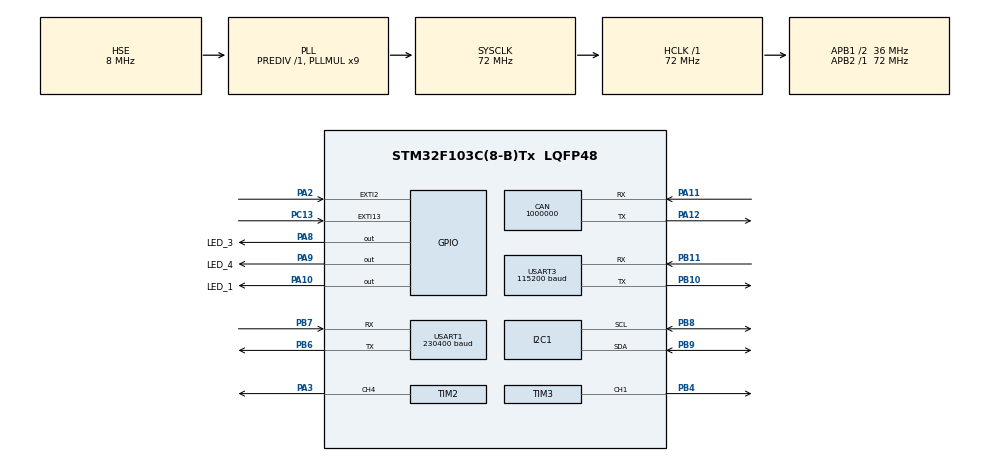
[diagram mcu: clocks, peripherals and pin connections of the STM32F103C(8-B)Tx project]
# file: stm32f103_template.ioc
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CAN.CalculateBaudRate=1000000
CAN.CalculateTimeBit=1000
CAN.CalculateTimeQuantum=83.33333333333333
Dma.I2C1_RX.2.Direction=DMA_PERIPH_TO_MEMORY
Dma.I2C1_RX.2.Instance=DMA1_Channel7
Dma.I2C1_RX.2.MemDataAlignment=DMA_MDATAALIGN_BYTE
Dma.I2C1_RX.2.MemInc=DMA_MINC_ENABLE
Dma.I2C1_RX.2.Mode=DMA_NORMAL
Dma.I2C1_RX.2.PeriphDataAlignment=DMA_PDATAALIGN_BYTE
Dma.I2C1_RX.2.PeriphInc=DMA_PINC_DISABLE
Dma.I2C1_RX.2.Priority=DMA_PRIORITY_VERY_HIGH
Dma.I2C1_TX.3.Direction=DMA_MEMORY_TO_PERIPH
Dma.I2C1_TX.3.Instance=DMA1_Channel6
Dma.I2C1_TX.3.MemDataAlignment=DMA_MDATAALIGN_BYTE
Dma.I2C1_TX.3.MemInc=DMA_MINC_ENABLE
Dma.I2C1_TX.3.Mode=DMA_NORMAL
Dma.I2C1_TX.3.PeriphDataAlignment=DMA_PDATAALIGN_BYTE
Dma.I2C1_TX.3.PeriphInc=DMA_PINC_DISABLE
Dma.I2C1_TX.3.Priority=DMA_PRIORITY_VERY_HIGH
Dma.Request0=USART1_TX
Dma.Request1=USART1_RX
Dma.Request2=I2C1_RX
Dma.Request3=I2C1_TX
Dma.Request4=USART3_RX
Dma.Request5=USART3_TX
Dma.USART1_RX.1.Direction=DMA_PERIPH_TO_MEMORY
Dma.USART1_RX.1.Instance=DMA1_Channel5
Dma.USART1_RX.1.MemDataAlignment=DMA_MDATAALIGN_BYTE
Dma.USART1_RX.1.MemInc=DMA_MINC_ENABLE
Dma.USART1_RX.1.Mode=DMA_NORMAL
Dma.USART1_RX.1.PeriphDataAlignment=DMA_PDATAALIGN_BYTE
Dma.USART1_RX.1.PeriphInc=DMA_PINC_DISABLE
Dma.USART1_RX.1.Priority=DMA_PRIORITY_VERY_HIGH
Dma.USART1_TX.0.Direction=DMA_MEMORY_TO_PERIPH
Dma.USART1_TX.0.Instance=DMA1_Channel4
Dma.USART1_TX.0.MemDataAlignment=DMA_MDATAALIGN_BYTE
Dma.USART1_TX.0.MemInc=DMA_MINC_ENABLE
Dma.USART1_TX.0.Mode=DMA_NORMAL
Dma.USART1_TX.0.PeriphDataAlignment=DMA_PDATAALIGN_BYTE
Dma.USART1_TX.0.PeriphInc=DMA_PINC_DISABLE
Dma.USART1_TX.0.Priority=DMA_PRIORITY_VERY_HIGH
Dma.USART3_RX.4.Direction=DMA_PERIPH_TO_MEMORY
Dma.USART3_RX.4.Instance=DMA1_Channel3
Dma.USART3_RX.4.MemDataAlignment=DMA_MDATAALIGN_BYTE
Dma.USART3_RX.4.MemInc=DMA_MINC_ENABLE
Dma.USART3_RX.4.Mode=DMA_NORMAL
Dma.USART3_RX.4.PeriphDataAlignment=DMA_PDATAALIGN_BYTE
Dma.USART3_RX.4.PeriphInc=DMA_PINC_DISABLE
Dma.USART3_RX.4.Priority=DMA_PRIORITY_VERY_HIGH
Dma.USART3_TX.5.Direction=DMA_MEMORY_TO_PERIPH
Dma.USART3_TX.5.Instance=DMA1_Channel2
Dma.USART3_TX.5.MemDataAlignment=DMA_MDATAALIGN_BYTE
Dma.USART3_TX.5.MemInc=DMA_MINC_ENABLE
Dma.USART3_TX.5.Mode=DMA_NORMAL
Dma.USART3_TX.5.PeriphDataAlignment=DMA_PDATAALIGN_BYTE
Dma.USART3_TX.5.PeriphInc=DMA_PINC_DISABLE
Dma.USART3_TX.5.Priority=DMA_PRIORITY_VERY_HIGH
FREERTOS.Tasks01=I2C_Task,0,128,i2c_task,As weak,NULL,Dynamic,NULL,NULL;USART_Task,1,298,usart_tsak,As weak,NULL,Dynamic,NULL,NULL;Light_Task,-3,128,light_task,As weak,NULL,Dynamic,NULL,NULL
FREERTOS.configMINIMAL_STACK_SIZE=128
I2C1.AddressingMode=I2C_ADDRESSINGMODE_7BIT
I2C1.DualAddressMode=I2C_DUALADDRESS_DISABLE
I2C1.GeneralCallMode=I2C_GENERALCALL_DISABLE
I2C1.I2C_Mode=I2C_Standard
I2C1.NoStretchMode=I2C_NOSTRETCH_DISABLE
I2C1.OwnAddress=0
Mcu.Family=STM32F1
Mcu.Name=STM32F103C(8-B)Tx
Mcu.Package=LQFP48
NVIC.USB_LP_CAN1_RX0_IRQn=true\:5\:0\:false\:false\:true\:true\:true\:true\:true
NVIC.DMA1_Channel2_IRQn=true\:5\:0\:false\:false\:true\:true\:false\:true\:true
NVIC.DMA1_Channel3_IRQn=true\:5\:0\:false\:false\:true\:true\:false\:true\:true
NVIC.DMA1_Channel4_IRQn=true\:5\:0\:false\:false\:true\:true\:false\:true\:true
NVIC.DMA1_Channel5_IRQn=true\:5\:0\:false\:false\:true\:true\:false\:true\:true
NVIC.DMA1_Channel6_IRQn=true\:5\:0\:false\:false\:true\:true\:false\:true\:true
NVIC.DMA1_Channel7_IRQn=true\:5\:0\:false\:false\:true\:true\:false\:true\:true
NVIC.EXTI15_10_IRQn=true\:5\:0\:false\:false\:true\:true\:true\:true\:true
NVIC.EXTI2_IRQn=true\:5\:0\:false\:false\:true\:true\:true\:true\:true
NVIC.I2C1_ER_IRQn=true\:5\:0\:false\:false\:true\:true\:true\:true\:true
NVIC.I2C1_EV_IRQn=true\:5\:0\:false\:false\:true\:true\:true\:true\:true
NVIC.PriorityGroup=NVIC_PRIORITYGROUP_4
NVIC.TIM1_UP_IRQn=true\:15\:0\:false\:false\:true\:false\:false\:true\:true
NVIC.TIM2_IRQn=true\:5\:0\:false\:false\:true\:true\:true\:true\:true
NVIC.TIM3_IRQn=true\:5\:0\:false\:false\:true\:true\:true\:true\:true
NVIC.TimeBase=TIM1_UP_IRQn
NVIC.TimeBaseIP=TIM1
NVIC.USART1_IRQn=true\:5\:0\:false\:false\:true\:true\:false\:true\:true
NVIC.USART3_IRQn=true\:5\:0\:false\:false\:true\:true\:true\:true\:true
PA10.GPIO_Label=LED_1
PA10.GPIO_ModeDefaultOutputPP=GPIO_MODE_OUTPUT_OD
PA10.GPIO_PuPd=GPIO_NOPULL
PA10.Signal=GPIO_Output
PA11.Mode=CAN_Activate
PA11.Signal=CAN_RX
PA12.Mode=CAN_Activate
PA12.Signal=CAN_TX
PA13.Mode=Serial_Wire
PA13.Signal=SYS_JTMS-SWDIO
PA14.Mode=Serial_Wire
PA14.Signal=SYS_JTCK-SWCLK
PA2.GPIO_PuPd=GPIO_NOPULL
PA2.Signal=GPXTI2
PA3.GPIO_Speed=GPIO_SPEED_FREQ_LOW
PA3.Signal=S_TIM2_CH4
PA8.GPIO_Label=LED_3
PA8.GPIO_ModeDefaultOutputPP=GPIO_MODE_OUTPUT_OD
PA8.GPIO_PuPd=GPIO_NOPULL
PA8.Signal=GPIO_Output
PA9.GPIO_Label=LED_4
PA9.GPIO_ModeDefaultOutputPP=GPIO_MODE_OUTPUT_OD
PA9.GPIO_PuPd=GPIO_NOPULL
PA9.Signal=GPIO_Output
PB10.Mode=Asynchronous
PB10.Signal=USART3_TX
PB11.Mode=Asynchronous
PB11.Signal=USART3_RX
PB4.GPIO_Speed=GPIO_SPEED_FREQ_LOW
PB4.Signal=S_TIM3_CH1
PB6.Mode=Asynchronous
PB6.Signal=USART1_TX
PB7.Mode=Asynchronous
PB7.Signal=USART1_RX
PB8.GPIO_Speed=GPIO_SPEED_FREQ_HIGH
PB8.Mode=I2C
PB8.Signal=I2C1_SCL
PB9.GPIO_Mode=GPIO_MODE_AF_OD
PB9.Mode=I2C
PB9.Signal=I2C1_SDA
PC13-TAMPER-RTC.GPIO_PuPd=GPIO_NOPULL
PC13-TAMPER-RTC.Signal=GPXTI13
PD0-OSC_IN.Mode=HSE-External-Oscillator
PD0-OSC_IN.Signal=RCC_OSC_IN
PD1-OSC_OUT.Mode=HSE-External-Oscillator
PD1-OSC_OUT.Signal=RCC_OSC_OUT
ProjectManager.HeapSize=0x200
ProjectManager.StackSize=0x400
ProjectManager.TargetToolchain=MDK-ARM V5.32
RCC.AHBFreq_Value=72000000
RCC.APB1CLKDivider=RCC_HCLK_DIV2
RCC.APB1Freq_Value=36000000
RCC.APB1TimFreq_Value=72000000
RCC.APB2Freq_Value=72000000
RCC.APB2TimFreq_Value=72000000
RCC.FLatency=FLASH_LATENCY_2
RCC.HCLKFreq_Value=72000000
RCC.PLLMUL=RCC_PLL_MUL9
RCC.PLLSourceVirtual=RCC_PLLSOURCE_HSE
RCC.SYSCLKFreq_VALUE=72000000
RCC.SYSCLKSource=RCC_SYSCLKSOURCE_PLLCLK
RCC.USBFreq_Value=72000000
SH.S_TIM2_CH4.0=TIM2_CH4,PWM Generation4 CH4
SH.S_TIM3_CH1.0=TIM3_CH1,PWM Generation1 CH1
TIM2.AutoReloadPreload=TIM_AUTORELOAD_PRELOAD_ENABLE
TIM2.Channel-PWM\ Generation4\ CH4=TIM_CHANNEL_4
TIM2.ClockDivision=TIM_CLOCKDIVISION_DIV1
TIM2.CounterMode=TIM_COUNTERMODE_UP
TIM2.OC4Preload_PWM=ENABLE
TIM2.OCFastMode_PWM-PWM\ Generation4\ CH4=TIM_OCFAST_DISABLE
TIM2.OCMode_PWM-PWM\ Generation4\ CH4=TIM_OCMODE_PWM1
TIM2.OCPolarity_4=TIM_OCPOLARITY_HIGH
TIM2.Period=89
TIM2.Prescaler=0
TIM2.Pulse-PWM\ Generation4\ CH4=0
TIM2.TIM_MasterOutputTrigger=TIM_TRGO_RESET
TIM2.TIM_MasterSlaveMode=TIM_MASTERSLAVEMODE_DISABLE
TIM3.AutoReloadPreload=TIM_AUTORELOAD_PRELOAD_ENABLE
TIM3.Channel-PWM\ Generation1\ CH1=TIM_CHANNEL_1
TIM3.Period=89
USART1.BaudRate=230400
USART1.Mode=MODE_TX_RX
USART1.Parity=PARITY_NONE
USART1.StopBits=STOPBITS_1
USART1.VirtualMode=VM_ASYNC
USART1.WordLength=WORDLENGTH_8B
USART3.BaudRate=115200
USART3.Mode=MODE_TX_RX
USART3.Parity=PARITY_NONE
USART3.StopBits=STOPBITS_1
USART3.VirtualMode=VM_ASYNC
USART3.WordLength=WORDLENGTH_8B
VP_FREERTOS_VS_CMSIS_V1.Mode=CMSIS_V1
VP_SYS_VS_tim1.Mode=TIM1
board=custom

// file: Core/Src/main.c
/* USER CODE BEGIN Header */
/**
  ******************************************************************************
  * @file           : main.c
  * @brief          : Main program body
  ******************************************************************************
  * @attention
  *
  * Copyright (c) 2026 STMicroelectronics.
  * All rights reserved.
  *
  * This software is licensed under terms that can be found in the LICENSE file
  * in the root directory of this software component.
  * If no LICENSE file comes with this software, it is provided AS-IS.
  *
  ******************************************************************************
  */
/* USER CODE END Header */
#include "main.h"
#include "cmsis_os.h"
#include "can.h"
#include "dma.h"
#include "i2c.h"
#include "tim.h"
#include "usart.h"
#include "gpio.h"

/* USER CODE BEGIN Includes */
#include "stm32_template.h"

/* USER CODE END Includes */

void SystemClock_Config(void);
void MX_FREERTOS_Init(void);

int main(void)
{

  /* MCU Configuration--------------------------------------------------------*/

  /* Reset of all peripherals, Initializes the Flash interface and the Systick. */
  HAL_Init();

  /* Configure the system clock */
  SystemClock_Config();

  /* Initialize all configured peripherals */
  MX_GPIO_Init();
  MX_DMA_Init();
  MX_I2C1_Init();
  MX_USART1_UART_Init();
  MX_USART3_UART_Init();
  MX_TIM2_Init();
  MX_TIM3_Init();
  MX_CAN_Init();
  /* USER CODE BEGIN 2 */
  stm32_template_init();

  /* USER CODE END 2 */

  /* Call init function for freertos objects (in cmsis_os2.c) */
  MX_FREERTOS_Init();

  /* Start scheduler */
  osKernelStart();

  /* We should never get here as control is now taken by the scheduler */

  /* Infinite loop */
  while (1)
  {

  }
}

void SystemClock_Config(void)
{
  RCC_OscInitTypeDef RCC_OscInitStruct = {0};
  RCC_ClkInitTypeDef RCC_ClkInitStruct = {0};

  /** Initializes the RCC Oscillators according to the specified parameters
  * in the RCC_OscInitTypeDef structure.
  */
  RCC_OscInitStruct.OscillatorType = RCC_OSCILLATORTYPE_HSE;
  RCC_OscInitStruct.HSEState = RCC_HSE_ON;
  RCC_OscInitStruct.HSEPredivValue = RCC_HSE_PREDIV_DIV1;
  RCC_OscInitStruct.HSIState = RCC_HSI_ON;
  RCC_OscInitStruct.PLL.PLLState = RCC_PLL_ON;
  RCC_OscInitStruct.PLL.PLLSource = RCC_PLLSOURCE_HSE;
  RCC_OscInitStruct.PLL.PLLMUL = RCC_PLL_MUL9;
  if (HAL_RCC_OscConfig(&RCC_OscInitStruct) != HAL_OK)
  {
    Error_Handler();
  }

  /** Initializes the CPU, AHB and APB buses clocks
  */
  RCC_ClkInitStruct.ClockType = RCC_CLOCKTYPE_HCLK|RCC_CLOCKTYPE_SYSCLK
                              |RCC_CLOCKTYPE_PCLK1|RCC_CLOCKTYPE_PCLK2;
  RCC_ClkInitStruct.SYSCLKSource = RCC_SYSCLKSOURCE_PLLCLK;
  RCC_ClkInitStruct.AHBCLKDivider = RCC_SYSCLK_DIV1;
  RCC_ClkInitStruct.APB1CLKDivider = RCC_HCLK_DIV2;
  RCC_ClkInitStruct.APB2CLKDivider = RCC_HCLK_DIV1;

  if (HAL_RCC_ClockConfig(&RCC_ClkInitStruct, FLASH_LATENCY_2) != HAL_OK)
  {
    Error_Handler();
  }
}

void HAL_TIM_PeriodElapsedCallback(TIM_HandleTypeDef *htim)
{
  if (htim->Instance == TIM1) {
    HAL_IncTick();
  }
}

void Error_Handler(void)
{
  __disable_irq();
  while (1)
  {
  }
}

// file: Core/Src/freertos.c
/* USER CODE BEGIN Header */
/**
  ******************************************************************************
  * File Name          : freertos.c
  * Description        : Code for freertos applications
  ******************************************************************************
  * @attention
  *
  * Copyright (c) 2026 STMicroelectronics.
  * All rights reserved.
  *
  * This software is licensed under terms that can be found in the LICENSE file
  * in the root directory of this software component.
  * If no LICENSE file comes with this software, it is provided AS-IS.
  *
  ******************************************************************************
  */
/* USER CODE END Header */

#include "FreeRTOS.h"
#include "task.h"
#include "main.h"
#include "cmsis_os.h"

osThreadId I2C_TaskHandle;
osThreadId USART_TaskHandle;
osThreadId Light_TaskHandle;

void i2c_task(void const * argument);
void usart_tsak(void const * argument);
void light_task(void const * argument);

void MX_FREERTOS_Init(void); /* (MISRA C 2004 rule 8.1) */

/* GetIdleTaskMemory prototype (linked to static allocation support) */
void vApplicationGetIdleTaskMemory( StaticTask_t **ppxIdleTaskTCBBuffer, StackType_t **ppxIdleTaskStackBuffer, uint32_t *pulIdleTaskStackSize );

/* USER CODE BEGIN GET_IDLE_TASK_MEMORY */
static StaticTask_t xIdleTaskTCBBuffer;
static StackType_t xIdleStack[configMINIMAL_STACK_SIZE];

void vApplicationGetIdleTaskMemory( StaticTask_t **ppxIdleTaskTCBBuffer, StackType_t **ppxIdleTaskStackBuffer, uint32_t *pulIdleTaskStackSize )
{
  *ppxIdleTaskTCBBuffer = &xIdleTaskTCBBuffer;
  *ppxIdleTaskStackBuffer = &xIdleStack[0];
  *pulIdleTaskStackSize = configMINIMAL_STACK_SIZE;
  /* place for user code */
}
/* USER CODE END GET_IDLE_TASK_MEMORY */

void MX_FREERTOS_Init(void) {

  /* Create the thread(s) */
  /* definition and creation of I2C_Task */
  osThreadDef(I2C_Task, i2c_task, osPriorityNormal, 0, 512);
  I2C_TaskHandle = osThreadCreate(osThread(I2C_Task), NULL);

  /* definition and creation of USART_Task */
  osThreadDef(USART_Task, usart_tsak, osPriorityBelowNormal, 0, 256);
  USART_TaskHandle = osThreadCreate(osThread(USART_Task), NULL);

  /* definition and creation of Light_Task */
  osThreadDef(Light_Task, light_task, osPriorityIdle, 0, 128);
  Light_TaskHandle = osThreadCreate(osThread(Light_Task), NULL);

}

__weak void i2c_task(void const * argument)
{
  for(;;)
  {
    osDelay(1);
  }
}

__weak void usart_tsak(void const * argument)
{
  for(;;)
  {
    osDelay(1);
  }
}

__weak void light_task(void const * argument)
{
  for(;;)
  {
    osDelay(1);
  }
}
